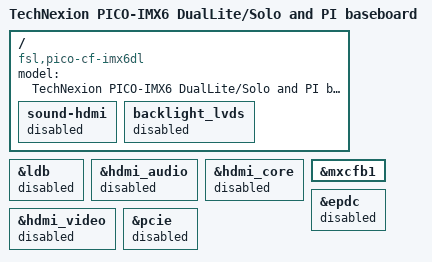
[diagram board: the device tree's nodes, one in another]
/*
 * Copyright 2018 Technexion Ltd.
 *
 * Author: Tapani Utriainen <tapani@technexion.com>
 *	   Richard Hu <richard.hu@technexion.com>
 *
 * This program is free software; you can redistribute it and/or modify
 * it under the terms of the GNU General Public License version 2 as
 * published by the Free Software Foundation.
 *
 */
/dts-v1/;

#include <dt-bindings/interrupt-controller/irq.h>
#include "imx6dl.dtsi"
#include "imx6qdl-pico.dtsi"
#include "baseboard_pico_pi.dtsi"
/ {
	model = "TechNexion PICO-IMX6 DualLite/Solo and PI baseboard";
	compatible = "fsl,pico-cf-imx6dl", "fsl,imx6dl";

	sound-hdmi {
		status = "disabled";
	};

	backlight_lvds {
		status = "disabled";
	};
};

&ldb {
	status = "disabled";
};

&hdmi_audio {
	status = "disabled";
};

&hdmi_core {
	status = "disabled";
};

&hdmi_video {
	status = "disabled";
};

&mxcfb1 {
	status = "okay";
};

&epdc {
	status = "disabled";
};

&pcie {
	status = "disabled";
};
